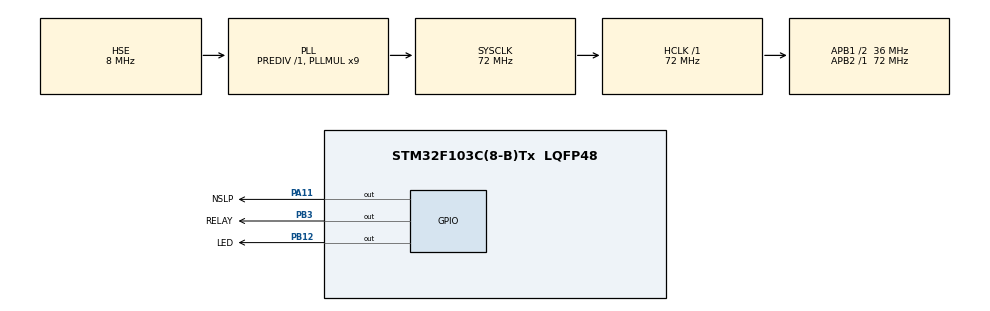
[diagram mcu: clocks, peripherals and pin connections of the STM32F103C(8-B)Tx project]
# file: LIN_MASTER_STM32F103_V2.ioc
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IWDG.Prescaler=IWDG_PRESCALER_4
IWDG.Reload=2048
Mcu.Family=STM32F1
Mcu.Name=STM32F103C(8-B)Tx
Mcu.Package=LQFP48
NVIC.PriorityGroup=NVIC_PRIORITYGROUP_4
PA11.GPIO_Label=NSLP
PA11.Signal=GPIO_Output
PA13.Mode=Serial_Wire
PA13.Signal=SYS_JTMS-SWDIO
PA14.Mode=Serial_Wire
PA14.Signal=SYS_JTCK-SWCLK
PB12.GPIO_Label=LED
PB12.Signal=GPIO_Output
PB3.GPIO_Label=RELAY
PB3.Signal=GPIO_Output
PD0-OSC_IN.Mode=HSE-External-Oscillator
PD0-OSC_IN.Signal=RCC_OSC_IN
PD1-OSC_OUT.Mode=HSE-External-Oscillator
PD1-OSC_OUT.Signal=RCC_OSC_OUT
ProjectManager.HeapSize=0x200
ProjectManager.StackSize=0x1000
ProjectManager.TargetToolchain=STM32CubeIDE
RCC.AHBFreq_Value=72000000
RCC.APB1CLKDivider=RCC_HCLK_DIV2
RCC.APB1Freq_Value=36000000
RCC.APB1TimFreq_Value=72000000
RCC.APB2Freq_Value=72000000
RCC.APB2TimFreq_Value=72000000
RCC.HCLKFreq_Value=72000000
RCC.PLLMUL=RCC_PLL_MUL9
RCC.PLLSourceVirtual=RCC_PLLSOURCE_HSE
RCC.SYSCLKFreq_VALUE=72000000
RCC.SYSCLKSource=RCC_SYSCLKSOURCE_PLLCLK
RCC.USBFreq_Value=72000000
VP_IWDG_VS_IWDG.Mode=IWDG_Activate
board=custom

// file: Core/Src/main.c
/* USER CODE BEGIN Header */
/**
  ******************************************************************************
  * @file           : main.c
  * @brief          : Main program body
  ******************************************************************************
  * @attention
  *
  * Copyright (c) 2025 STMicroelectronics.
  * All rights reserved.
  *
  * This software is licensed under terms that can be found in the LICENSE file
  * in the root directory of this software component.
  * If no LICENSE file comes with this software, it is provided AS-IS.
  *
  *1) Подключить LIN Haker и найти скорость передачи данных
  *2) Вычитать в каком адресе и как изменяется информация в фрейме
  *3) Выставить макросы в соответсвии с параметрами
  ******************************************************************************
  */
/* USER CODE END Header */
#include "main.h"

/* USER CODE BEGIN Includes */
//#include <math.h>
#include <string.h>
#include <stdbool.h>
#include "portable_LIN.h"
/* USER CODE END Includes */

IWDG_HandleTypeDef hiwdg;

/* USER CODE BEGIN PV */

extern LIN_Receive_State_t lin_state;
extern LIN_FrameStatus_t lin_frame_state;

LIN_Frame_t New_Frame = {0};

/* USER CODE END PV */

void SystemClock_Config(void);
static void MX_GPIO_Init(void);
static void MX_IWDG_Init(void);

int main(void)
{

  /* MCU Configuration--------------------------------------------------------*/

  /* Reset of all peripherals, Initializes the Flash interface and the Systick. */
  HAL_Init();

  /* Configure the system clock */
  SystemClock_Config();

  /* Initialize all configured peripherals */
  MX_GPIO_Init();
  MX_IWDG_Init();
  /* USER CODE BEGIN 2 */
  RELAY_GPIO_Port->ODR &= ~RELAY_Pin;
  UART_Init_System(UART_DAUD_RATE, APB2_CLK_MHz);
  GPIOA->ODR |= NSLP_Pin;
  GPIOB->ODR &= ~LED_Pin;

  /* USER CODE END 2 */

  /* Infinite loop */
  /* USER CODE BEGIN WHILE */
  while (1)
  {

	  if(UART_Read_From_Buffer(&New_Frame) != true){
		  HAL_Delay(1);
	  }else{
		  if(New_Frame.PID == PID_RECESIVE_FRAME)
		  {
			  if(New_Frame.data[NUM_BYTE_DATA] == CHECK_BYTE_ON)
			  {
				  HAL_GPIO_WritePin(RELAY_GPIO_Port, RELAY_Pin, SET);
			  }else{

				  HAL_GPIO_WritePin(RELAY_GPIO_Port, RELAY_Pin, RESET);
			  }

		  }
	  }

	  HAL_IWDG_Refresh(&hiwdg);

    /* USER CODE END WHILE */

  }
}

void SystemClock_Config(void)
{
  RCC_OscInitTypeDef RCC_OscInitStruct = {0};
  RCC_ClkInitTypeDef RCC_ClkInitStruct = {0};

  /** Initializes the RCC Oscillators according to the specified parameters
  * in the RCC_OscInitTypeDef structure.
  */
  RCC_OscInitStruct.OscillatorType = RCC_OSCILLATORTYPE_LSI|RCC_OSCILLATORTYPE_HSE;
  RCC_OscInitStruct.HSEState = RCC_HSE_ON;
  RCC_OscInitStruct.HSEPredivValue = RCC_HSE_PREDIV_DIV1;
  RCC_OscInitStruct.HSIState = RCC_HSI_ON;
  RCC_OscInitStruct.LSIState = RCC_LSI_ON;
  RCC_OscInitStruct.PLL.PLLState = RCC_PLL_ON;
  RCC_OscInitStruct.PLL.PLLSource = RCC_PLLSOURCE_HSE;
  RCC_OscInitStruct.PLL.PLLMUL = RCC_PLL_MUL9;
  if (HAL_RCC_OscConfig(&RCC_OscInitStruct) != HAL_OK)
  {
    Error_Handler();
  }

  /** Initializes the CPU, AHB and APB buses clocks
  */
  RCC_ClkInitStruct.ClockType = RCC_CLOCKTYPE_HCLK|RCC_CLOCKTYPE_SYSCLK
                              |RCC_CLOCKTYPE_PCLK1|RCC_CLOCKTYPE_PCLK2;
  RCC_ClkInitStruct.SYSCLKSource = RCC_SYSCLKSOURCE_PLLCLK;
  RCC_ClkInitStruct.AHBCLKDivider = RCC_SYSCLK_DIV1;
  RCC_ClkInitStruct.APB1CLKDivider = RCC_HCLK_DIV2;
  RCC_ClkInitStruct.APB2CLKDivider = RCC_HCLK_DIV1;

  if (HAL_RCC_ClockConfig(&RCC_ClkInitStruct, FLASH_LATENCY_2) != HAL_OK)
  {
    Error_Handler();
  }
}

static void MX_IWDG_Init(void)
{

  hiwdg.Instance = IWDG;
  hiwdg.Init.Prescaler = IWDG_PRESCALER_4;
  hiwdg.Init.Reload = 2048;
  if (HAL_IWDG_Init(&hiwdg) != HAL_OK)
  {
    Error_Handler();
  }

}

static void MX_GPIO_Init(void)
{
  GPIO_InitTypeDef GPIO_InitStruct = {0};

  /* GPIO Ports Clock Enable */
  __HAL_RCC_GPIOD_CLK_ENABLE();
  __HAL_RCC_GPIOB_CLK_ENABLE();
  __HAL_RCC_GPIOA_CLK_ENABLE();

  /*Configure GPIO pin Output Level */
  HAL_GPIO_WritePin(GPIOB, LED_Pin|RELAY_Pin, GPIO_PIN_RESET);

  /*Configure GPIO pin Output Level */
  HAL_GPIO_WritePin(NSLP_GPIO_Port, NSLP_Pin, GPIO_PIN_RESET);

  /*Configure GPIO pins : LED_Pin RELAY_Pin */
  GPIO_InitStruct.Pin = LED_Pin|RELAY_Pin;
  GPIO_InitStruct.Mode = GPIO_MODE_OUTPUT_PP;
  GPIO_InitStruct.Pull = GPIO_NOPULL;
  GPIO_InitStruct.Speed = GPIO_SPEED_FREQ_LOW;
  HAL_GPIO_Init(GPIOB, &GPIO_InitStruct);

  /*Configure GPIO pin : NSLP_Pin */
  GPIO_InitStruct.Pin = NSLP_Pin;
  GPIO_InitStruct.Mode = GPIO_MODE_OUTPUT_PP;
  GPIO_InitStruct.Pull = GPIO_NOPULL;
  GPIO_InitStruct.Speed = GPIO_SPEED_FREQ_LOW;
  HAL_GPIO_Init(NSLP_GPIO_Port, &GPIO_InitStruct);

}

void Error_Handler(void)
{
  __disable_irq();
  while (1)
  {
  }
}
